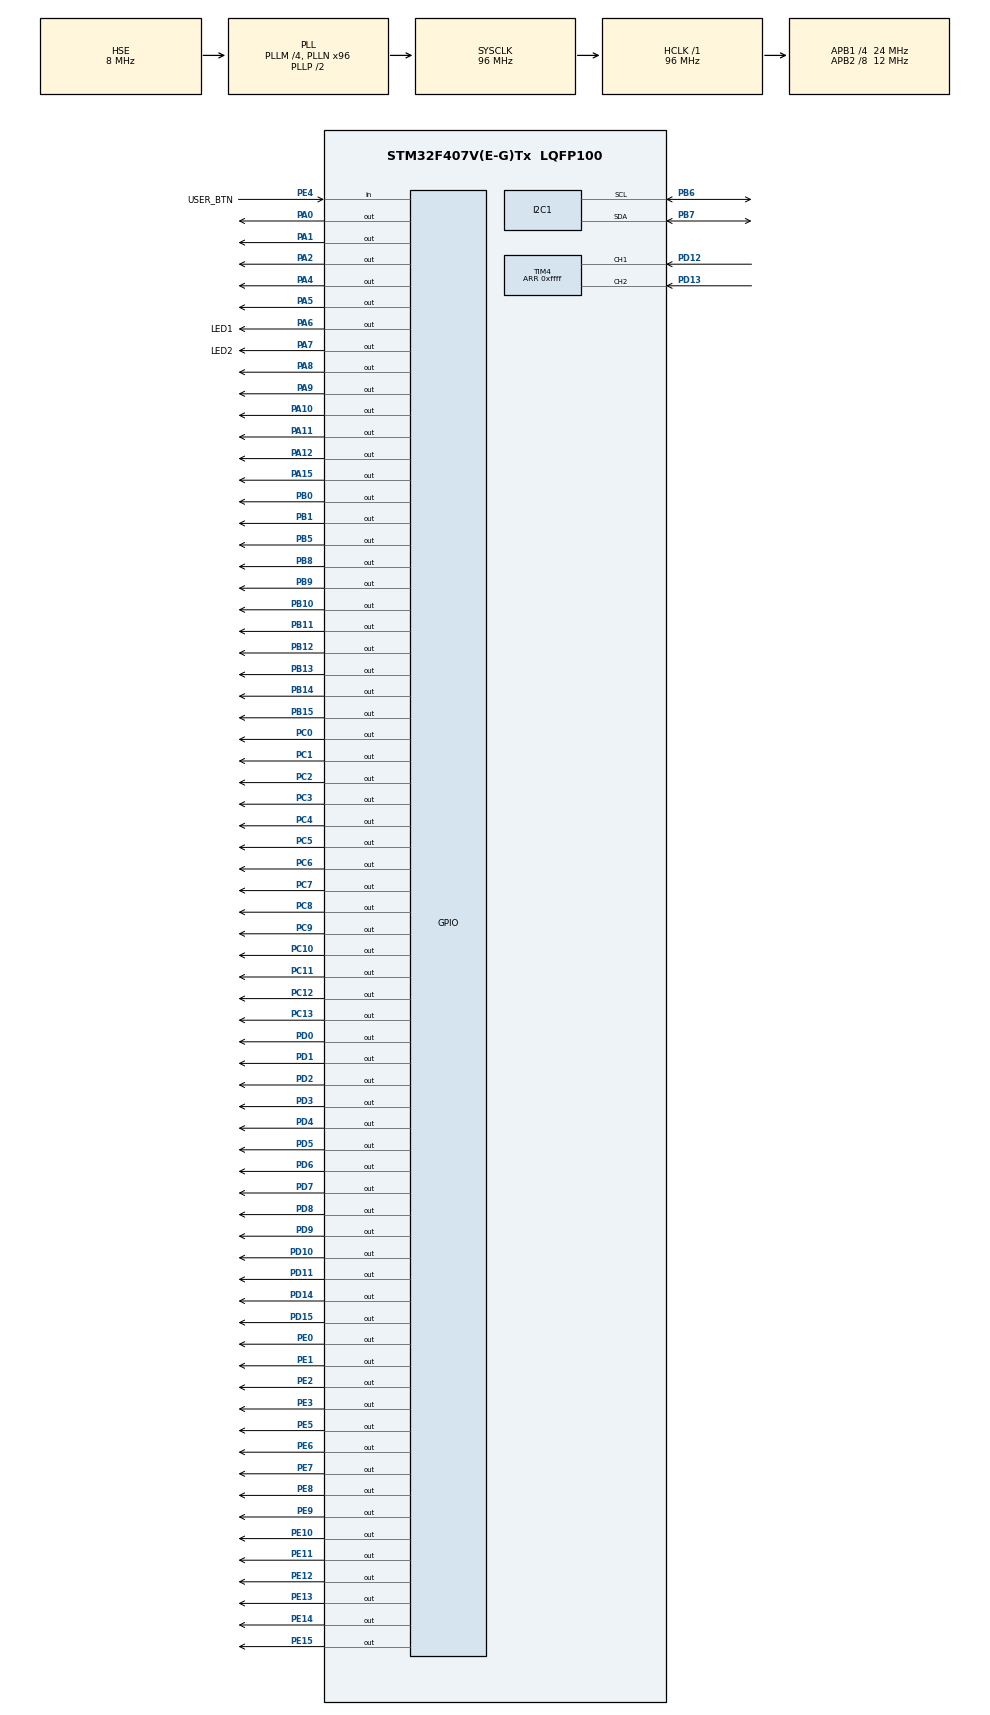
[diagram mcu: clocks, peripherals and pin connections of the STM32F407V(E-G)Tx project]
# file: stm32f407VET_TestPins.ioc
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FREERTOS.Tasks01=uiTask,15,256,StartUiTask,As weak,NULL,Static,defaultTaskBuffer,defaultTaskControlBlock
FREERTOS.configGENERATE_RUN_TIME_STATS=1
FREERTOS.configRECORD_STACK_HIGH_ADDRESS=1
I2C1.I2C_Mode=I2C_Fast
Mcu.Family=STM32F4
Mcu.Name=STM32F407V(E-G)Tx
Mcu.Package=LQFP100
NVIC.I2C1_ER_IRQn=true\:0\:0\:false\:false\:true\:false\:true\:true
NVIC.I2C1_EV_IRQn=true\:0\:0\:false\:false\:true\:false\:true\:true
NVIC.PriorityGroup=NVIC_PRIORITYGROUP_4
NVIC.TIM7_IRQn=true\:0\:0\:false\:false\:true\:false\:false\:true
NVIC.TimeBase=TIM7_IRQn
NVIC.TimeBaseIP=TIM7
PA0-WKUP.Signal=GPIO_Output
PA1.Signal=GPIO_Output
PA10.Signal=GPIO_Output
PA11.Signal=GPIO_Output
PA12.Signal=GPIO_Output
PA13.Mode=Trace_Asynchronous_SW
PA13.Signal=SYS_JTMS-SWDIO
PA14.Mode=Trace_Asynchronous_SW
PA14.Signal=SYS_JTCK-SWCLK
PA15.Signal=GPIO_Output
PA2.Signal=GPIO_Output
PA4.Signal=GPIO_Output
PA5.Signal=GPIO_Output
PA6.GPIO_Label=LED1
PA6.Signal=GPIO_Output
PA7.GPIO_Label=LED2
PA7.Signal=GPIO_Output
PA8.Signal=GPIO_Output
PA9.Signal=GPIO_Output
PB0.Signal=GPIO_Output
PB1.Signal=GPIO_Output
PB10.Signal=GPIO_Output
PB11.Signal=GPIO_Output
PB12.Signal=GPIO_Output
PB13.Signal=GPIO_Output
PB14.Signal=GPIO_Output
PB15.Signal=GPIO_Output
PB3.Mode=Trace_Asynchronous_SW
PB3.Signal=SYS_JTDO-SWO
PB5.Signal=GPIO_Output
PB6.Mode=I2C
PB6.Signal=I2C1_SCL
PB7.Mode=I2C
PB7.Signal=I2C1_SDA
PB8.Signal=GPIO_Output
PB9.Signal=GPIO_Output
PC0.Signal=GPIO_Output
PC1.Signal=GPIO_Output
PC10.Signal=GPIO_Output
PC11.Signal=GPIO_Output
PC12.Signal=GPIO_Output
PC13-ANTI_TAMP.Signal=GPIO_Output
PC14-OSC32_IN.Mode=LSE-External-Oscillator
PC14-OSC32_IN.Signal=RCC_OSC32_IN
PC15-OSC32_OUT.Mode=LSE-External-Oscillator
PC15-OSC32_OUT.Signal=RCC_OSC32_OUT
PC2.Signal=GPIO_Output
PC3.Signal=GPIO_Output
PC4.Signal=GPIO_Output
PC5.Signal=GPIO_Output
PC6.Signal=GPIO_Output
PC7.Signal=GPIO_Output
PC8.Signal=GPIO_Output
PC9.Signal=GPIO_Output
PD0.Signal=GPIO_Output
PD1.Signal=GPIO_Output
PD10.Signal=GPIO_Output
PD11.Signal=GPIO_Output
PD12.GPIO_PuPd=GPIO_PULLUP
PD12.Signal=S_TIM4_CH1
PD13.GPIO_PuPd=GPIO_PULLUP
PD13.Signal=S_TIM4_CH2
PD14.Signal=GPIO_Output
PD15.Signal=GPIO_Output
PD2.Signal=GPIO_Output
PD3.Signal=GPIO_Output
PD4.Signal=GPIO_Output
PD5.Signal=GPIO_Output
PD6.Signal=GPIO_Output
PD7.Signal=GPIO_Output
PD8.Signal=GPIO_Output
PD9.Signal=GPIO_Output
PE0.Signal=GPIO_Output
PE1.Signal=GPIO_Output
PE10.Signal=GPIO_Output
PE11.Signal=GPIO_Output
PE12.Signal=GPIO_Output
PE13.Signal=GPIO_Output
PE14.Signal=GPIO_Output
PE15.Signal=GPIO_Output
PE2.Signal=GPIO_Output
PE3.Signal=GPIO_Output
PE4.GPIO_Label=USER_BTN
PE4.GPIO_PuPd=GPIO_PULLUP
PE4.Signal=GPIO_Input
PE5.Signal=GPIO_Output
PE6.Signal=GPIO_Output
PE7.Signal=GPIO_Output
PE8.Signal=GPIO_Output
PE9.Signal=GPIO_Output
PH0-OSC_IN.Mode=HSE-External-Oscillator
PH0-OSC_IN.Signal=RCC_OSC_IN
PH1-OSC_OUT.Mode=HSE-External-Oscillator
PH1-OSC_OUT.Signal=RCC_OSC_OUT
ProjectManager.HeapSize=0x200
ProjectManager.StackSize=0x400
ProjectManager.TargetToolchain=STM32CubeIDE
RCC.48MHZClocksFreq_Value=48000000
RCC.AHBFreq_Value=96000000
RCC.APB1CLKDivider=RCC_HCLK_DIV4
RCC.APB1Freq_Value=24000000
RCC.APB1TimFreq_Value=48000000
RCC.APB2CLKDivider=RCC_HCLK_DIV8
RCC.APB2Freq_Value=12000000
RCC.APB2TimFreq_Value=24000000
RCC.CortexFreq_Value=96000000
RCC.HCLKFreq_Value=96000000
RCC.HSE_VALUE=8000000
RCC.HSI_VALUE=16000000
RCC.PLLM=4
RCC.PLLN=96
RCC.PLLSourceVirtual=RCC_PLLSOURCE_HSE
RCC.RCC_RTC_Clock_Source=RCC_RTCCLKSOURCE_LSE
RCC.RCC_RTC_Clock_SourceVirtual=RCC_RTCCLKSOURCE_LSE
RCC.SYSCLKFreq_VALUE=96000000
RCC.SYSCLKSource=RCC_SYSCLKSOURCE_PLLCLK
RCC.VCOOutputFreq_Value=192000000
SH.S_TIM4_CH1.0=TIM4_CH1,Encoder_Interface
SH.S_TIM4_CH2.0=TIM4_CH2,Encoder_Interface
TIM4.IC1Filter=10
TIM4.IC2Filter=10
TIM4.Period=0xffff
TIM8.AutoReloadPreload=TIM_AUTORELOAD_PRELOAD_ENABLE
TIM8.Period=210
TIM8.Prescaler=1199
TIM8.TIM_MasterOutputTrigger=TIM_TRGO_UPDATE
TIM8.TIM_MasterSlaveMode=TIM_MASTERSLAVEMODE_ENABLE
VP_FREERTOS_VS_CMSIS_V2.Mode=CMSIS_V2
VP_RTC_VS_RTC_Activate.Mode=RTC_Enabled
VP_RTC_VS_RTC_Calendar.Mode=RTC_Calendar
VP_SYS_VS_tim7.Mode=TIM7
VP_TIM8_VS_ClockSourceINT.Mode=Internal
VP_TIM8_VS_ClockSourceITR.Mode=TriggerSource_ITR0
VP_TIM8_VS_ControllerModeReset.Mode=Reset Mode
board=custom

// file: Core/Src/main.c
/* USER CODE BEGIN Header */
/**
  ******************************************************************************
  * @file           : main.c
  * @brief          : Main program body
  ******************************************************************************
  * @attention
  *
  * <h2><center>&copy; Copyright (c) 2020 STMicroelectronics.
  * All rights reserved.</center></h2>
  *
  * This software component is licensed by ST under BSD 3-Clause license,
  * the "License"; You may not use this file except in compliance with the
  * License. You may obtain a copy of the License at:
  *                        opensource.org/licenses/BSD-3-Clause
  *
  ******************************************************************************
  */
/* USER CODE END Header */
#include "main.h"
#include "cmsis_os.h"

/* USER CODE BEGIN Includes */
//#include "../../../disp_tft/ssd1306_tests.h"
//#include "../../../disp_tft/ssd1306.h"
//#include "../../../BLE/bletask.h"
#include <memory.h>

//#include "../../../stm32dev/ina3221/ina3221.h"

/* USER CODE END Includes */

typedef StaticTask_t osStaticThreadDef_t;

I2C_HandleTypeDef hi2c1;

RTC_HandleTypeDef hrtc;

TIM_HandleTypeDef htim4;
TIM_HandleTypeDef htim8;

/* Definitions for uiTask */
osThreadId_t uiTaskHandle;
uint32_t defaultTaskBuffer[ 256 ];
osStaticThreadDef_t defaultTaskControlBlock;
const osThreadAttr_t uiTask_attributes = {
  .name = "uiTask",
  .stack_mem = &defaultTaskBuffer[0],
  .stack_size = sizeof(defaultTaskBuffer),
  .cb_mem = &defaultTaskControlBlock,
  .cb_size = sizeof(defaultTaskControlBlock),
  .priority = (osPriority_t) osPriorityLow7,
};

void SystemClock_Config(void);
static void MX_GPIO_Init(void);
static void MX_I2C1_Init(void);
static void MX_RTC_Init(void);
static void MX_TIM8_Init(void);
static void MX_TIM4_Init(void);
void StartUiTask(void *argument);

int main(void)
{

  /* MCU Configuration--------------------------------------------------------*/

  /* Reset of all peripherals, Initializes the Flash interface and the Systick. */
  HAL_Init();

  /* Configure the system clock */
  SystemClock_Config();

  /* Initialize all configured peripherals */
  MX_GPIO_Init();
  MX_I2C1_Init();
  MX_RTC_Init();
  MX_TIM8_Init();
  MX_TIM4_Init();

  /* Init scheduler */
  osKernelInitialize();

  /* Create the thread(s) */
  /* creation of uiTask */
  uiTaskHandle = osThreadNew(StartUiTask, NULL, &uiTask_attributes);

  /* Start scheduler */
  osKernelStart();

  /* We should never get here as control is now taken by the scheduler */
  /* Infinite loop */
  while (1)
  {

  }
}

void SystemClock_Config(void)
{
  RCC_OscInitTypeDef RCC_OscInitStruct = {0};
  RCC_ClkInitTypeDef RCC_ClkInitStruct = {0};
  RCC_PeriphCLKInitTypeDef PeriphClkInitStruct = {0};

  /** Configure the main internal regulator output voltage
  */
  __HAL_RCC_PWR_CLK_ENABLE();
  __HAL_PWR_VOLTAGESCALING_CONFIG(PWR_REGULATOR_VOLTAGE_SCALE1);
  /** Initializes the RCC Oscillators according to the specified parameters
  * in the RCC_OscInitTypeDef structure.
  */
  RCC_OscInitStruct.OscillatorType = RCC_OSCILLATORTYPE_HSE|RCC_OSCILLATORTYPE_LSE;
  RCC_OscInitStruct.HSEState = RCC_HSE_ON;
  RCC_OscInitStruct.LSEState = RCC_LSE_ON;
  RCC_OscInitStruct.PLL.PLLState = RCC_PLL_ON;
  RCC_OscInitStruct.PLL.PLLSource = RCC_PLLSOURCE_HSE;
  RCC_OscInitStruct.PLL.PLLM = 4;
  RCC_OscInitStruct.PLL.PLLN = 96;
  RCC_OscInitStruct.PLL.PLLP = RCC_PLLP_DIV2;
  RCC_OscInitStruct.PLL.PLLQ = 4;
  if (HAL_RCC_OscConfig(&RCC_OscInitStruct) != HAL_OK)
  {
    Error_Handler();
  }
  /** Initializes the CPU, AHB and APB buses clocks
  */
  RCC_ClkInitStruct.ClockType = RCC_CLOCKTYPE_HCLK|RCC_CLOCKTYPE_SYSCLK
                              |RCC_CLOCKTYPE_PCLK1|RCC_CLOCKTYPE_PCLK2;
  RCC_ClkInitStruct.SYSCLKSource = RCC_SYSCLKSOURCE_PLLCLK;
  RCC_ClkInitStruct.AHBCLKDivider = RCC_SYSCLK_DIV1;
  RCC_ClkInitStruct.APB1CLKDivider = RCC_HCLK_DIV4;
  RCC_ClkInitStruct.APB2CLKDivider = RCC_HCLK_DIV8;

  if (HAL_RCC_ClockConfig(&RCC_ClkInitStruct, FLASH_LATENCY_3) != HAL_OK)
  {
    Error_Handler();
  }
  PeriphClkInitStruct.PeriphClockSelection = RCC_PERIPHCLK_RTC;
  PeriphClkInitStruct.RTCClockSelection = RCC_RTCCLKSOURCE_LSE;
  if (HAL_RCCEx_PeriphCLKConfig(&PeriphClkInitStruct) != HAL_OK)
  {
    Error_Handler();
  }
}

static void MX_I2C1_Init(void)
{

  hi2c1.Instance = I2C1;
  hi2c1.Init.ClockSpeed = 400000;
  hi2c1.Init.DutyCycle = I2C_DUTYCYCLE_2;
  hi2c1.Init.OwnAddress1 = 0;
  hi2c1.Init.AddressingMode = I2C_ADDRESSINGMODE_7BIT;
  hi2c1.Init.DualAddressMode = I2C_DUALADDRESS_DISABLE;
  hi2c1.Init.OwnAddress2 = 0;
  hi2c1.Init.GeneralCallMode = I2C_GENERALCALL_DISABLE;
  hi2c1.Init.NoStretchMode = I2C_NOSTRETCH_DISABLE;
  if (HAL_I2C_Init(&hi2c1) != HAL_OK)
  {
    Error_Handler();
  }

}

static void MX_RTC_Init(void)
{

  RTC_TimeTypeDef sTime = {0};
  RTC_DateTypeDef sDate = {0};

  /** Initialize RTC Only
  */
  hrtc.Instance = RTC;
  hrtc.Init.HourFormat = RTC_HOURFORMAT_24;
  hrtc.Init.AsynchPrediv = 127;
  hrtc.Init.SynchPrediv = 255;
  hrtc.Init.OutPut = RTC_OUTPUT_DISABLE;
  hrtc.Init.OutPutPolarity = RTC_OUTPUT_POLARITY_HIGH;
  hrtc.Init.OutPutType = RTC_OUTPUT_TYPE_OPENDRAIN;
  if (HAL_RTC_Init(&hrtc) != HAL_OK)
  {
    Error_Handler();
  }

  /* USER CODE BEGIN Check_RTC_BKUP */
  return;
  /* USER CODE END Check_RTC_BKUP */

  /** Initialize RTC and set the Time and Date
  */
  sTime.Hours = 0x0;
  sTime.Minutes = 0x0;
  sTime.Seconds = 0x0;
  sTime.DayLightSaving = RTC_DAYLIGHTSAVING_NONE;
  sTime.StoreOperation = RTC_STOREOPERATION_RESET;
  if (HAL_RTC_SetTime(&hrtc, &sTime, RTC_FORMAT_BCD) != HAL_OK)
  {
    Error_Handler();
  }
  sDate.WeekDay = RTC_WEEKDAY_MONDAY;
  sDate.Month = RTC_MONTH_JANUARY;
  sDate.Date = 0x1;
  sDate.Year = 0x0;

  if (HAL_RTC_SetDate(&hrtc, &sDate, RTC_FORMAT_BCD) != HAL_OK)
  {
    Error_Handler();
  }

}

static void MX_TIM4_Init(void)
{

  TIM_Encoder_InitTypeDef sConfig = {0};
  TIM_MasterConfigTypeDef sMasterConfig = {0};

  htim4.Instance = TIM4;
  htim4.Init.Prescaler = 0;
  htim4.Init.CounterMode = TIM_COUNTERMODE_UP;
  htim4.Init.Period = 0xffff;
  htim4.Init.ClockDivision = TIM_CLOCKDIVISION_DIV1;
  htim4.Init.AutoReloadPreload = TIM_AUTORELOAD_PRELOAD_DISABLE;
  sConfig.EncoderMode = TIM_ENCODERMODE_TI1;
  sConfig.IC1Polarity = TIM_ICPOLARITY_RISING;
  sConfig.IC1Selection = TIM_ICSELECTION_DIRECTTI;
  sConfig.IC1Prescaler = TIM_ICPSC_DIV1;
  sConfig.IC1Filter = 10;
  sConfig.IC2Polarity = TIM_ICPOLARITY_RISING;
  sConfig.IC2Selection = TIM_ICSELECTION_DIRECTTI;
  sConfig.IC2Prescaler = TIM_ICPSC_DIV1;
  sConfig.IC2Filter = 10;
  if (HAL_TIM_Encoder_Init(&htim4, &sConfig) != HAL_OK)
  {
    Error_Handler();
  }
  sMasterConfig.MasterOutputTrigger = TIM_TRGO_RESET;
  sMasterConfig.MasterSlaveMode = TIM_MASTERSLAVEMODE_DISABLE;
  if (HAL_TIMEx_MasterConfigSynchronization(&htim4, &sMasterConfig) != HAL_OK)
  {
    Error_Handler();
  }

}

static void MX_TIM8_Init(void)
{

  TIM_ClockConfigTypeDef sClockSourceConfig = {0};
  TIM_SlaveConfigTypeDef sSlaveConfig = {0};
  TIM_MasterConfigTypeDef sMasterConfig = {0};

  htim8.Instance = TIM8;
  htim8.Init.Prescaler = 1199;
  htim8.Init.CounterMode = TIM_COUNTERMODE_UP;
  htim8.Init.Period = 210;
  htim8.Init.ClockDivision = TIM_CLOCKDIVISION_DIV1;
  htim8.Init.RepetitionCounter = 0;
  htim8.Init.AutoReloadPreload = TIM_AUTORELOAD_PRELOAD_ENABLE;
  if (HAL_TIM_Base_Init(&htim8) != HAL_OK)
  {
    Error_Handler();
  }
  sClockSourceConfig.ClockSource = TIM_CLOCKSOURCE_INTERNAL;
  if (HAL_TIM_ConfigClockSource(&htim8, &sClockSourceConfig) != HAL_OK)
  {
    Error_Handler();
  }
  sSlaveConfig.SlaveMode = TIM_SLAVEMODE_RESET;
  sSlaveConfig.InputTrigger = TIM_TS_ITR0;
  if (HAL_TIM_SlaveConfigSynchro(&htim8, &sSlaveConfig) != HAL_OK)
  {
    Error_Handler();
  }
  sMasterConfig.MasterOutputTrigger = TIM_TRGO_UPDATE;
  sMasterConfig.MasterSlaveMode = TIM_MASTERSLAVEMODE_ENABLE;
  if (HAL_TIMEx_MasterConfigSynchronization(&htim8, &sMasterConfig) != HAL_OK)
  {
    Error_Handler();
  }

}

static void MX_GPIO_Init(void)
{
  GPIO_InitTypeDef GPIO_InitStruct = {0};

  /* GPIO Ports Clock Enable */
  __HAL_RCC_GPIOE_CLK_ENABLE();
  __HAL_RCC_GPIOC_CLK_ENABLE();
  __HAL_RCC_GPIOH_CLK_ENABLE();
  __HAL_RCC_GPIOA_CLK_ENABLE();
  __HAL_RCC_GPIOB_CLK_ENABLE();
  __HAL_RCC_GPIOD_CLK_ENABLE();

  /*Configure GPIO pin Output Level */
  HAL_GPIO_WritePin(GPIOE, GPIO_PIN_2|GPIO_PIN_3|GPIO_PIN_5|GPIO_PIN_6
                          |GPIO_PIN_7|GPIO_PIN_8|GPIO_PIN_9|GPIO_PIN_10
                          |GPIO_PIN_11|GPIO_PIN_12|GPIO_PIN_13|GPIO_PIN_14
                          |GPIO_PIN_15|GPIO_PIN_0|GPIO_PIN_1, GPIO_PIN_RESET);

  /*Configure GPIO pin Output Level */
  HAL_GPIO_WritePin(GPIOC, GPIO_PIN_13|GPIO_PIN_0|GPIO_PIN_1|GPIO_PIN_2
                          |GPIO_PIN_3|GPIO_PIN_4|GPIO_PIN_5|GPIO_PIN_6
                          |GPIO_PIN_7|GPIO_PIN_8|GPIO_PIN_9|GPIO_PIN_10
                          |GPIO_PIN_11|GPIO_PIN_12, GPIO_PIN_RESET);

  /*Configure GPIO pin Output Level */
  HAL_GPIO_WritePin(GPIOA, GPIO_PIN_0|GPIO_PIN_1|GPIO_PIN_2|GPIO_PIN_4
                          |GPIO_PIN_5|LED1_Pin|LED2_Pin|GPIO_PIN_8
                          |GPIO_PIN_9|GPIO_PIN_10|GPIO_PIN_11|GPIO_PIN_12
                          |GPIO_PIN_15, GPIO_PIN_RESET);

  /*Configure GPIO pin Output Level */
  HAL_GPIO_WritePin(GPIOB, GPIO_PIN_0|GPIO_PIN_1|GPIO_PIN_10|GPIO_PIN_11
                          |GPIO_PIN_12|GPIO_PIN_13|GPIO_PIN_14|GPIO_PIN_15
                          |GPIO_PIN_5|GPIO_PIN_8|GPIO_PIN_9, GPIO_PIN_RESET);

  /*Configure GPIO pin Output Level */
  HAL_GPIO_WritePin(GPIOD, GPIO_PIN_8|GPIO_PIN_9|GPIO_PIN_10|GPIO_PIN_11
                          |GPIO_PIN_14|GPIO_PIN_15|GPIO_PIN_0|GPIO_PIN_1
                          |GPIO_PIN_2|GPIO_PIN_3|GPIO_PIN_4|GPIO_PIN_5
                          |GPIO_PIN_6|GPIO_PIN_7, GPIO_PIN_RESET);

  /*Configure GPIO pins : PE2 PE3 PE5 PE6
                           PE7 PE8 PE9 PE10
                           PE11 PE12 PE13 PE14
                           PE15 PE0 PE1 */
  GPIO_InitStruct.Pin = GPIO_PIN_2|GPIO_PIN_3|GPIO_PIN_5|GPIO_PIN_6
                          |GPIO_PIN_7|GPIO_PIN_8|GPIO_PIN_9|GPIO_PIN_10
                          |GPIO_PIN_11|GPIO_PIN_12|GPIO_PIN_13|GPIO_PIN_14
                          |GPIO_PIN_15|GPIO_PIN_0|GPIO_PIN_1;
  GPIO_InitStruct.Mode = GPIO_MODE_OUTPUT_PP;
  GPIO_InitStruct.Pull = GPIO_NOPULL;
  GPIO_InitStruct.Speed = GPIO_SPEED_FREQ_LOW;
  HAL_GPIO_Init(GPIOE, &GPIO_InitStruct);

  /*Configure GPIO pin : USER_BTN_Pin */
  GPIO_InitStruct.Pin = USER_BTN_Pin;
  GPIO_InitStruct.Mode = GPIO_MODE_INPUT;
  GPIO_InitStruct.Pull = GPIO_PULLUP;
  HAL_GPIO_Init(USER_BTN_GPIO_Port, &GPIO_InitStruct);

  /*Configure GPIO pins : PC13 PC0 PC1 PC2
                           PC3 PC4 PC5 PC6
                           PC7 PC8 PC9 PC10
                           PC11 PC12 */
  GPIO_InitStruct.Pin = GPIO_PIN_13|GPIO_PIN_0|GPIO_PIN_1|GPIO_PIN_2
                          |GPIO_PIN_3|GPIO_PIN_4|GPIO_PIN_5|GPIO_PIN_6
                          |GPIO_PIN_7|GPIO_PIN_8|GPIO_PIN_9|GPIO_PIN_10
                          |GPIO_PIN_11|GPIO_PIN_12;
  GPIO_InitStruct.Mode = GPIO_MODE_OUTPUT_PP;
  GPIO_InitStruct.Pull = GPIO_NOPULL;
  GPIO_InitStruct.Speed = GPIO_SPEED_FREQ_LOW;
  HAL_GPIO_Init(GPIOC, &GPIO_InitStruct);

  /*Configure GPIO pins : PA0 PA1 PA2 PA4
                           PA5 LED1_Pin LED2_Pin PA8
                           PA9 PA10 PA11 PA12
                           PA15 */
  GPIO_InitStruct.Pin = GPIO_PIN_0|GPIO_PIN_1|GPIO_PIN_2|GPIO_PIN_4
                          |GPIO_PIN_5|LED1_Pin|LED2_Pin|GPIO_PIN_8
                          |GPIO_PIN_9|GPIO_PIN_10|GPIO_PIN_11|GPIO_PIN_12
                          |GPIO_PIN_15;
  GPIO_InitStruct.Mode = GPIO_MODE_OUTPUT_PP;
  GPIO_InitStruct.Pull = GPIO_NOPULL;
  GPIO_InitStruct.Speed = GPIO_SPEED_FREQ_LOW;
  HAL_GPIO_Init(GPIOA, &GPIO_InitStruct);

  /*Configure GPIO pins : PB0 PB1 PB10 PB11
                           PB12 PB13 PB14 PB15
                           PB5 PB8 PB9 */
  GPIO_InitStruct.Pin = GPIO_PIN_0|GPIO_PIN_1|GPIO_PIN_10|GPIO_PIN_11
                          |GPIO_PIN_12|GPIO_PIN_13|GPIO_PIN_14|GPIO_PIN_15
                          |GPIO_PIN_5|GPIO_PIN_8|GPIO_PIN_9;
  GPIO_InitStruct.Mode = GPIO_MODE_OUTPUT_PP;
  GPIO_InitStruct.Pull = GPIO_NOPULL;
  GPIO_InitStruct.Speed = GPIO_SPEED_FREQ_LOW;
  HAL_GPIO_Init(GPIOB, &GPIO_InitStruct);

  /*Configure GPIO pins : PD8 PD9 PD10 PD11
                           PD14 PD15 PD0 PD1
                           PD2 PD3 PD4 PD5
                           PD6 PD7 */
  GPIO_InitStruct.Pin = GPIO_PIN_8|GPIO_PIN_9|GPIO_PIN_10|GPIO_PIN_11
                          |GPIO_PIN_14|GPIO_PIN_15|GPIO_PIN_0|GPIO_PIN_1
                          |GPIO_PIN_2|GPIO_PIN_3|GPIO_PIN_4|GPIO_PIN_5
                          |GPIO_PIN_6|GPIO_PIN_7;
  GPIO_InitStruct.Mode = GPIO_MODE_OUTPUT_PP;
  GPIO_InitStruct.Pull = GPIO_NOPULL;
  GPIO_InitStruct.Speed = GPIO_SPEED_FREQ_LOW;
  HAL_GPIO_Init(GPIOD, &GPIO_InitStruct);

}

__weak void StartUiTask(void *argument)
{
  /* USER CODE BEGIN 5 */

    for (;;) {
    	osDelay(1000);
    }

  /* USER CODE END 5 */
}

void HAL_TIM_PeriodElapsedCallback(TIM_HandleTypeDef *htim)
{
  if (htim->Instance == TIM7) {
    HAL_IncTick();
  }
}

void Error_Handler(void)
{
	for (;;) {
	}
}

#ifdef  USE_FULL_ASSERT
/**
  * @brief  Reports the name of the source file and the source line number
  *         where the assert_param error has occurred.
  * @param  file: pointer to the source file name
  * @param  line: assert_param error line source number
  * @retval None
  */
void assert_failed(uint8_t *file, uint32_t line)
{
  /* USER CODE BEGIN 6 */
	Error_Handler();
  /* User can add his own implementation to report the file name and line number,
     tex: printf("Wrong parameters value: file %s on line %d\r\n", file, line) */
  /* USER CODE END 6 */
}
#endif /* USE_FULL_ASSERT */

/************************ (C) COPYRIGHT STMicroelectronics *****END OF FILE****/

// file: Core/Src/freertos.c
/* USER CODE BEGIN Header */
/**
  ******************************************************************************
  * File Name          : freertos.c
  * Description        : Code for freertos applications
  ******************************************************************************
  * @attention
  *
  * <h2><center>&copy; Copyright (c) 2020 STMicroelectronics.
  * All rights reserved.</center></h2>
  *
  * This software component is licensed by ST under Ultimate Liberty license
  * SLA0044, the "License"; You may not use this file except in compliance with
  * the License. You may obtain a copy of the License at:
  *                             www.st.com/SLA0044
  *
  ******************************************************************************
  */
/* USER CODE END Header */

#include "FreeRTOS.h"
#include "task.h"
#include "main.h"

/* Hook prototypes */
void configureTimerForRunTimeStats(void);
unsigned long getRunTimeCounterValue(void);

/* USER CODE BEGIN 1 */
/* Functions needed when configGENERATE_RUN_TIME_STATS is on */
__weak void configureTimerForRunTimeStats(void)
{

}

__weak unsigned long getRunTimeCounterValue(void)
{
return 0;
}
/* USER CODE END 1 */

/************************ (C) COPYRIGHT STMicroelectronics *****END OF FILE****/
